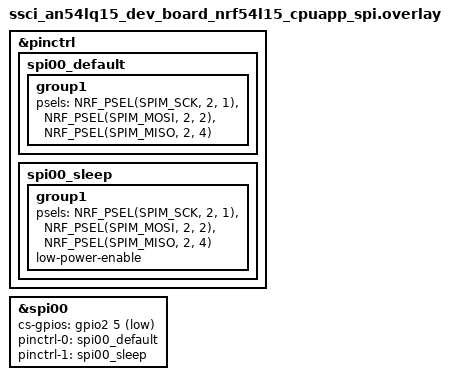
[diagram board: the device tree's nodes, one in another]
/*
 * SPDX-License-Identifier: Apache-2.0
 *
 * Optional SPI00 bus for applications targeting
 * ssci_an54lq15_dev_board/nrf54l15/cpuapp.
 *
 * Enable CONFIG_SPI in the application configuration and pass this file via
 * EXTRA_DTC_OVERLAY_FILE. Add external-device nodes to &spi00 in the
 * application-specific overlay.
 */

&pinctrl {
	spi00_default: spi00_default {
		group1 {
			psels = <NRF_PSEL(SPIM_SCK, 2, 1)>,
				<NRF_PSEL(SPIM_MOSI, 2, 2)>,
				<NRF_PSEL(SPIM_MISO, 2, 4)>;
		};
	};

	spi00_sleep: spi00_sleep {
		group1 {
			psels = <NRF_PSEL(SPIM_SCK, 2, 1)>,
				<NRF_PSEL(SPIM_MOSI, 2, 2)>,
				<NRF_PSEL(SPIM_MISO, 2, 4)>;
			low-power-enable;
		};
	};
};

&spi00 {
	status = "okay";
	cs-gpios = <&gpio2 5 GPIO_ACTIVE_LOW>;
	pinctrl-0 = <&spi00_default>;
	pinctrl-1 = <&spi00_sleep>;
	pinctrl-names = "default", "sleep";
};
